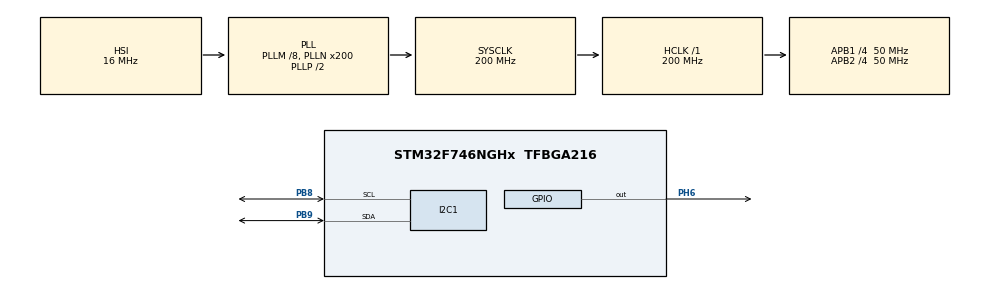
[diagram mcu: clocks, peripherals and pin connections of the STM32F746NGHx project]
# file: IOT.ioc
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I2C1.Timing=0x00C0EAFF
Mcu.Family=STM32F7
Mcu.Name=STM32F746NGHx
Mcu.Package=TFBGA216
NVIC.PriorityGroup=NVIC_PRIORITYGROUP_4
PA13.Mode=Serial_Wire
PA13.Signal=SYS_JTMS-SWDIO
PA14.Mode=Serial_Wire
PA14.Signal=SYS_JTCK-SWCLK
PB8.Mode=I2C
PB8.Signal=I2C1_SCL
PB9.Mode=I2C
PB9.Signal=I2C1_SDA
PH6.Signal=GPIO_Output
ProjectManager.HeapSize=0x200
ProjectManager.StackSize=0x400
ProjectManager.TargetToolchain=STM32CubeIDE
RCC.AHBFreq_Value=200000000
RCC.APB1CLKDivider=RCC_HCLK_DIV4
RCC.APB1Freq_Value=50000000
RCC.APB1TimFreq_Value=100000000
RCC.APB2CLKDivider=RCC_HCLK_DIV4
RCC.APB2Freq_Value=50000000
RCC.APB2TimFreq_Value=100000000
RCC.CortexFreq_Value=200000000
RCC.HCLKFreq_Value=200000000
RCC.HSE_VALUE=25000000
RCC.HSI_VALUE=16000000
RCC.LSE_VALUE=32768
RCC.PLLM=8
RCC.PLLN=200
RCC.SYSCLKFreq_VALUE=200000000
RCC.SYSCLKSource=RCC_SYSCLKSOURCE_PLLCLK
RCC.USBFreq_Value=200000000
RCC.VCOOutputFreq_Value=400000000
TIM1.Prescaler=99
VP_TIM1_VS_ClockSourceINT.Mode=Internal
board=custom

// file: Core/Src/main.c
/* USER CODE BEGIN Header */
/**
  ******************************************************************************
  * @file           : main.c
  * @brief          : Main program body - ngon ngon
  ******************************************************************************
  * @attention
  *
  * <h2><center>&copy; Copyright (c) 2021 STMicroelectronics.
  * All rights reserved.</center></h2>
  *
  * This software component is licensed by ST under BSD 3-Clause license,
  * the "License"; You may not use this file except in compliance with the
  * License. You may obtain a copy of the License at:
  *                        opensource.org/licenses/BSD-3-Clause
  *
  ******************************************************************************
  */
/* USER CODE END Header */
#include "main.h"

/* USER CODE BEGIN Includes */
#include "bh1750.h"

/* USER CODE END Includes */

/* USER CODE BEGIN PD */
#define DHT11_PORT GPIOH
#define DHT11_PIN  GPIO_PIN_6
/* USER CODE END PD */

I2C_HandleTypeDef hi2c1;

TIM_HandleTypeDef htim1;

void SystemClock_Config(void);
static void MX_GPIO_Init(void);
static void MX_I2C1_Init(void);
static void MX_TIM1_Init(void);

/* USER CODE BEGIN 0 */
uint8_t RHI, RHD, TCI, TCD, SUM;
uint32_t pMillis, cMillis;
float tCelsius = 0;
float tFahrenheit = 0;
float RH = 0;

// Cảm biến áng sáng
float BH1750_lux;
void microDelay(uint16_t us)
{
	__HAL_TIM_SET_COUNTER(&htim1,0);
    while ((uint16_t)__HAL_TIM_GET_COUNTER(&htim1) < us);
}

uint8_t DHT11_Start (void)
{
  uint8_t Response = 0;
  GPIO_InitTypeDef GPIO_InitStructPrivate = {0};
  GPIO_InitStructPrivate.Pin = DHT11_PIN;
  GPIO_InitStructPrivate.Mode = GPIO_MODE_OUTPUT_OD;
  GPIO_InitStructPrivate.Speed = GPIO_SPEED_FREQ_LOW;
  GPIO_InitStructPrivate.Pull = GPIO_NOPULL;
  HAL_GPIO_Init(DHT11_PORT, &GPIO_InitStructPrivate); // set the pin as output
  HAL_GPIO_WritePin (DHT11_PORT, DHT11_PIN, 0);   // pull the pin low
  HAL_Delay(20);   // wait for 20ms
  HAL_GPIO_WritePin (DHT11_PORT, DHT11_PIN, 1);   // pull the pin high
  microDelay (30);   // wait for 30us
  GPIO_InitStructPrivate.Mode = GPIO_MODE_INPUT;
  GPIO_InitStructPrivate.Pull = GPIO_PULLUP;
  HAL_GPIO_Init(DHT11_PORT, &GPIO_InitStructPrivate); // set the pin as input
  microDelay (40);
  if (!(HAL_GPIO_ReadPin (DHT11_PORT, DHT11_PIN)))
  {
    microDelay (80);
    if ((HAL_GPIO_ReadPin (DHT11_PORT, DHT11_PIN))) Response = 1;
  }
  pMillis = HAL_GetTick();
  cMillis = HAL_GetTick();
  while ((HAL_GPIO_ReadPin (DHT11_PORT, DHT11_PIN)) && pMillis + 2 > cMillis)
  {
    cMillis = HAL_GetTick();
  }
  return Response;
}

uint8_t DHT11_Read (void)
{
  uint8_t a,b;
  for (a=0;a<8;a++)
  {
    pMillis = HAL_GetTick();
    cMillis = HAL_GetTick();
    while (!(HAL_GPIO_ReadPin (DHT11_PORT, DHT11_PIN)) && pMillis + 2 > cMillis)
    {  // wait for the pin to go high
      cMillis = HAL_GetTick();
    }
    microDelay (40);   // wait for 40 us
    if (!(HAL_GPIO_ReadPin (DHT11_PORT, DHT11_PIN)))   // if the pin is low
      b&= ~(1<<(7-a));
    else
      b|= (1<<(7-a));
    pMillis = HAL_GetTick();
    cMillis = HAL_GetTick();
    while ((HAL_GPIO_ReadPin (DHT11_PORT, DHT11_PIN)) && pMillis + 2 > cMillis)
    {  // wait for the pin to go low
      cMillis = HAL_GetTick();
    }
  }
  return b;
}
/* USER CODE END 0 */

int main(void)
{

  /* MCU Configuration--------------------------------------------------------*/

  /* Reset of all peripherals, Initializes the Flash interface and the Systick. */
  HAL_Init();

  /* Configure the system clock */
  SystemClock_Config();

  /* Initialize all configured peripherals */
  MX_GPIO_Init();
  MX_I2C1_Init();
  MX_TIM1_Init();
  /* USER CODE BEGIN 2 */
  HAL_TIM_Base_Start(&htim1);
  HAL_Delay(1000);

  /* USER CODE END 2 */
  BH1750_Init(&hi2c1);
  BH1750_SetMode(CONTINUOUS_HIGH_RES_MODE_2);
  /* Infinite loop */
  while (1)
  {

    /* USER CODE BEGIN 3 */

	  // CẢM BIẾN ÁNH SÁNG BH1750
	  BH1750_ReadLight(&BH1750_lux);
	  // CẢM BIẾN NHIỆT ĐỘ & ĐỘ ẨM
	    if(DHT11_Start())
	    {
	      RHI = DHT11_Read(); // Relative humidity integral
	      RHD = DHT11_Read(); // Relative humidity decimal
	      TCI = DHT11_Read(); // Celsius integral
	      TCD = DHT11_Read(); // Celsius decimal
	      SUM = DHT11_Read(); // Check sum
	      if (RHI + RHD + TCI + TCD == SUM)
	      {
	        tCelsius = (float)TCI + (float)(TCD/10.0);  // độ C
	        RH = (float)RHI + (float)(RHD/10.0);  // độ ẩm
	      }
	    }

  }
  /* USER CODE END 3 */
}

void SystemClock_Config(void)
{
  RCC_OscInitTypeDef RCC_OscInitStruct = {0};
  RCC_ClkInitTypeDef RCC_ClkInitStruct = {0};
  RCC_PeriphCLKInitTypeDef PeriphClkInitStruct = {0};

  /** Configure the main internal regulator output voltage
  */
  __HAL_RCC_PWR_CLK_ENABLE();
  __HAL_PWR_VOLTAGESCALING_CONFIG(PWR_REGULATOR_VOLTAGE_SCALE1);
  /** Initializes the RCC Oscillators according to the specified parameters
  * in the RCC_OscInitTypeDef structure.
  */
  RCC_OscInitStruct.OscillatorType = RCC_OSCILLATORTYPE_HSI;
  RCC_OscInitStruct.HSIState = RCC_HSI_ON;
  RCC_OscInitStruct.HSICalibrationValue = RCC_HSICALIBRATION_DEFAULT;
  RCC_OscInitStruct.PLL.PLLState = RCC_PLL_ON;
  RCC_OscInitStruct.PLL.PLLSource = RCC_PLLSOURCE_HSI;
  RCC_OscInitStruct.PLL.PLLM = 8;
  RCC_OscInitStruct.PLL.PLLN = 200;
  RCC_OscInitStruct.PLL.PLLP = RCC_PLLP_DIV2;
  RCC_OscInitStruct.PLL.PLLQ = 2;
  if (HAL_RCC_OscConfig(&RCC_OscInitStruct) != HAL_OK)
  {
    Error_Handler();
  }
  /** Activate the Over-Drive mode
  */
  if (HAL_PWREx_EnableOverDrive() != HAL_OK)
  {
    Error_Handler();
  }
  /** Initializes the CPU, AHB and APB buses clocks
  */
  RCC_ClkInitStruct.ClockType = RCC_CLOCKTYPE_HCLK|RCC_CLOCKTYPE_SYSCLK
                              |RCC_CLOCKTYPE_PCLK1|RCC_CLOCKTYPE_PCLK2;
  RCC_ClkInitStruct.SYSCLKSource = RCC_SYSCLKSOURCE_PLLCLK;
  RCC_ClkInitStruct.AHBCLKDivider = RCC_SYSCLK_DIV1;
  RCC_ClkInitStruct.APB1CLKDivider = RCC_HCLK_DIV4;
  RCC_ClkInitStruct.APB2CLKDivider = RCC_HCLK_DIV4;

  if (HAL_RCC_ClockConfig(&RCC_ClkInitStruct, FLASH_LATENCY_6) != HAL_OK)
  {
    Error_Handler();
  }
  PeriphClkInitStruct.PeriphClockSelection = RCC_PERIPHCLK_I2C1;
  PeriphClkInitStruct.I2c1ClockSelection = RCC_I2C1CLKSOURCE_PCLK1;
  if (HAL_RCCEx_PeriphCLKConfig(&PeriphClkInitStruct) != HAL_OK)
  {
    Error_Handler();
  }
}

static void MX_I2C1_Init(void)
{

  hi2c1.Instance = I2C1;
  hi2c1.Init.Timing = 0x00C0EAFF;
  hi2c1.Init.OwnAddress1 = 0;
  hi2c1.Init.AddressingMode = I2C_ADDRESSINGMODE_7BIT;
  hi2c1.Init.DualAddressMode = I2C_DUALADDRESS_DISABLE;
  hi2c1.Init.OwnAddress2 = 0;
  hi2c1.Init.OwnAddress2Masks = I2C_OA2_NOMASK;
  hi2c1.Init.GeneralCallMode = I2C_GENERALCALL_DISABLE;
  hi2c1.Init.NoStretchMode = I2C_NOSTRETCH_DISABLE;
  if (HAL_I2C_Init(&hi2c1) != HAL_OK)
  {
    Error_Handler();
  }
  /** Configure Analogue filter
  */
  if (HAL_I2CEx_ConfigAnalogFilter(&hi2c1, I2C_ANALOGFILTER_ENABLE) != HAL_OK)
  {
    Error_Handler();
  }
  /** Configure Digital filter
  */
  if (HAL_I2CEx_ConfigDigitalFilter(&hi2c1, 0) != HAL_OK)
  {
    Error_Handler();
  }

}

static void MX_TIM1_Init(void)
{

  TIM_ClockConfigTypeDef sClockSourceConfig = {0};
  TIM_MasterConfigTypeDef sMasterConfig = {0};

  htim1.Instance = TIM1;
  htim1.Init.Prescaler = 99;
  htim1.Init.CounterMode = TIM_COUNTERMODE_UP;
  htim1.Init.Period = 65535;
  htim1.Init.ClockDivision = TIM_CLOCKDIVISION_DIV1;
  htim1.Init.RepetitionCounter = 0;
  htim1.Init.AutoReloadPreload = TIM_AUTORELOAD_PRELOAD_DISABLE;
  if (HAL_TIM_Base_Init(&htim1) != HAL_OK)
  {
    Error_Handler();
  }
  sClockSourceConfig.ClockSource = TIM_CLOCKSOURCE_INTERNAL;
  if (HAL_TIM_ConfigClockSource(&htim1, &sClockSourceConfig) != HAL_OK)
  {
    Error_Handler();
  }
  sMasterConfig.MasterOutputTrigger = TIM_TRGO_RESET;
  sMasterConfig.MasterOutputTrigger2 = TIM_TRGO2_RESET;
  sMasterConfig.MasterSlaveMode = TIM_MASTERSLAVEMODE_DISABLE;
  if (HAL_TIMEx_MasterConfigSynchronization(&htim1, &sMasterConfig) != HAL_OK)
  {
    Error_Handler();
  }

}

static void MX_GPIO_Init(void)
{
  GPIO_InitTypeDef GPIO_InitStruct = {0};

  /* GPIO Ports Clock Enable */
  __HAL_RCC_GPIOB_CLK_ENABLE();
  __HAL_RCC_GPIOA_CLK_ENABLE();
  __HAL_RCC_GPIOH_CLK_ENABLE();

  /*Configure GPIO pin Output Level */
  HAL_GPIO_WritePin(GPIOH, GPIO_PIN_6, GPIO_PIN_RESET);

  /*Configure GPIO pin : PH6 */
  GPIO_InitStruct.Pin = GPIO_PIN_6;
  GPIO_InitStruct.Mode = GPIO_MODE_OUTPUT_PP;
  GPIO_InitStruct.Pull = GPIO_NOPULL;
  GPIO_InitStruct.Speed = GPIO_SPEED_FREQ_LOW;
  HAL_GPIO_Init(GPIOH, &GPIO_InitStruct);

}

void Error_Handler(void)
{
  __disable_irq();
  while (1)
  {
  }
}

/************************ (C) COPYRIGHT STMicroelectronics *****END OF FILE****/
